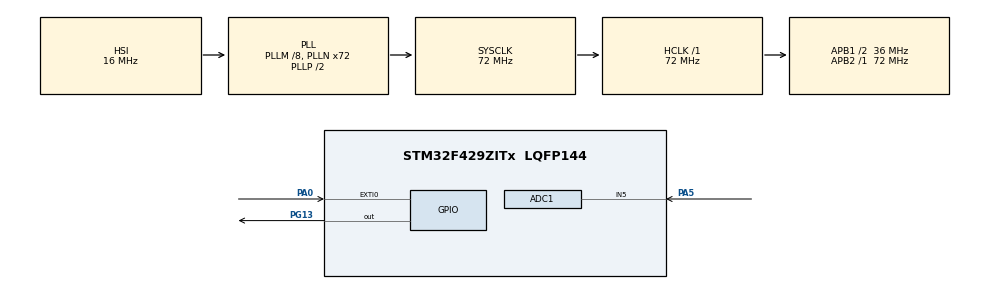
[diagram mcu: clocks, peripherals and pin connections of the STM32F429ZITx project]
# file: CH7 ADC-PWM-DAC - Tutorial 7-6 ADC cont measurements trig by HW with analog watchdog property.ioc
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ADC1.Channel-1\#ChannelRegularConversion=ADC_CHANNEL_5
ADC1.ContinuousConvMode=ENABLE
ADC1.EnableAnalogWatchDog=true
ADC1.HighThreshold=3586
ADC1.ITMode=ENABLE
ADC1.LowThreshold=512
ADC1.NbrOfConversionFlag=1
ADC1.Rank-1\#ChannelRegularConversion=1
ADC1.SamplingTime-1\#ChannelRegularConversion=ADC_SAMPLETIME_480CYCLES
ADC1.WatchdogChannel=ADC_CHANNEL_5
ADC1.master=1
Mcu.Family=STM32F4
Mcu.Name=STM32F429ZITx
Mcu.Package=LQFP144
NVIC.ADC_IRQn=true\:1\:0\:true\:false\:true\:true\:true\:true
NVIC.EXTI0_IRQn=true\:1\:0\:true\:false\:true\:true\:true\:true
NVIC.PriorityGroup=NVIC_PRIORITYGROUP_1
PA0/WKUP.Signal=GPXTI0
PA5.Signal=ADCx_IN5
PG13.Signal=GPIO_Output
ProjectManager.HeapSize=0x200
ProjectManager.StackSize=0x400
ProjectManager.TargetToolchain=STM32CubeIDE
RCC.48MHZClocksFreq_Value=20571428.57142857
RCC.AHBFreq_Value=72000000
RCC.APB1CLKDivider=RCC_HCLK_DIV2
RCC.APB1Freq_Value=36000000
RCC.APB1TimFreq_Value=72000000
RCC.APB2Freq_Value=72000000
RCC.APB2TimFreq_Value=72000000
RCC.CortexFreq_Value=72000000
RCC.HCLKFreq_Value=72000000
RCC.HSE_VALUE=8000000
RCC.HSI_VALUE=16000000
RCC.LSE_VALUE=32768
RCC.PLLM=8
RCC.PLLN=72
RCC.PLLQ=7
RCC.SYSCLKFreq_VALUE=72000000
RCC.SYSCLKSource=RCC_SYSCLKSOURCE_PLLCLK
RCC.VCOOutputFreq_Value=144000000
SH.ADCx_IN5.0=ADC2_IN5
SH.ADCx_IN5.1=ADC1_IN5,IN5
board=STM32F429I-DISC1

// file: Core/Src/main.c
/* USER CODE BEGIN Header */
/**
  ******************************************************************************
  * @file           : main.c
  * @brief          : Main program body
  ******************************************************************************
  * @attention
  *
  * Copyright (c) 2024 STMicroelectronics.
  * All rights reserved.
  *
  * This software is licensed under terms that can be found in the LICENSE file
  * in the root directory of this software component.
  * If no LICENSE file comes with this software, it is provided AS-IS.
  *
  ******************************************************************************
  */

	/***************************** Tutorial Tags ******************************
	 ADC continuous measurements
	 Hardware trigger EXTI line
	 **************************************************************************/

	/* 7.4.1 ADC Usage C Language: ******************************************
	* Tutorial 7-6: Usage of the ADC module with analog watchdog property, the C code
	*

    In this tutorial, form a project with the following specificvation:

    ADC2 Channel 5 is configured to be triggered by the onboard user button to take
    measurements of a potentiometer in continous mode in the infinite loop.
    The watchdog property of the ADC is set with low and high threshold levels
    as 512 and 3586, respectively. We should also enable the end of conversion and
    watchdog interrupts.

    After the project is compiled and run, ADC is triggered when the onboard
	button is pressed. Once 100 conversions are done, obtained values are summed and
	averaged in an infinite loop. If the analog value is above or below the threshold
	levels, then the watchdog interrupt is triggered during the conversion operation.
	Then, the variable adcWatchdogFlag is set and the onboard green LED connected
	to pin PG13 is turned on in the watchdog callback function. The adcWatchdogFlag
	is checked in the infinite loop in the main function. If this variable has been set in
	the callback function, then the ADC is stopped and onboard green LED is turned
	off after 2 s.
	***************************************************************************/

/* USER CODE END Header */
#include "main.h"

/* USER CODE BEGIN PD */
#define CONV_NUM 100
/* USER CODE END PD */

ADC_HandleTypeDef hadc1;

/* USER CODE BEGIN PV */
//uint8_t adcWatchdogFlag;
//uint8_t adcState;

uint32_t adcValue [CONV_NUM];
uint32_t adcSum, adcAve;
int32_t   counter;
uint8_t adcWatchdogFlag, flag_count;

/* USER CODE END PV */

void SystemClock_Config(void);
static void MX_GPIO_Init(void);
static void MX_ADC1_Init(void);

int main(void)
{

  /* MCU Configuration--------------------------------------------------------*/

  /* Reset of all peripherals, Initializes the Flash interface and the Systick. */
  HAL_Init();

  /* Configure the system clock */
  SystemClock_Config();

  /* Initialize all configured peripherals */
  MX_GPIO_Init();
  MX_ADC1_Init();

  /* Infinite loop */
  /* USER CODE BEGIN WHILE */
  while (1)
  {
   if(adcWatchdogFlag){

	   adcWatchdogFlag = 0;
	   HAL_Delay(2000);
	   HAL_GPIO_WritePin(GPIOG, GPIO_PIN_13, GPIO_PIN_RESET);

	   // Stop ADC if watchdog flag has set more than 5 times
	   flag_count++;
	   if (flag_count > 5){
		   HAL_ADC_Stop_IT(&hadc1);
	   }
	   else{
		   HAL_ADC_Start_IT(&hadc1);
	   }

	   HAL_Delay(100);
   }
   else if (counter == CONV_NUM){
	   for (int i=0; i<CONV_NUM; ++i){
		   adcSum += adcValue[i];
	   }
	   adcAve  = adcSum/CONV_NUM;
	   adcSum =  0; counter = 0;
	   HAL_ADC_Start_IT(&hadc1);
   }
  }
  /* USER CODE END 3 */
}

void SystemClock_Config(void)
{
  RCC_OscInitTypeDef RCC_OscInitStruct = {0};
  RCC_ClkInitTypeDef RCC_ClkInitStruct = {0};

  /** Configure the main internal regulator output voltage
  */
  __HAL_RCC_PWR_CLK_ENABLE();
  __HAL_PWR_VOLTAGESCALING_CONFIG(PWR_REGULATOR_VOLTAGE_SCALE3);

  /** Initializes the RCC Oscillators according to the specified parameters
  * in the RCC_OscInitTypeDef structure.
  */
  RCC_OscInitStruct.OscillatorType = RCC_OSCILLATORTYPE_HSI;
  RCC_OscInitStruct.HSIState = RCC_HSI_ON;
  RCC_OscInitStruct.HSICalibrationValue = RCC_HSICALIBRATION_DEFAULT;
  RCC_OscInitStruct.PLL.PLLState = RCC_PLL_ON;
  RCC_OscInitStruct.PLL.PLLSource = RCC_PLLSOURCE_HSI;
  RCC_OscInitStruct.PLL.PLLM = 8;
  RCC_OscInitStruct.PLL.PLLN = 72;
  RCC_OscInitStruct.PLL.PLLP = RCC_PLLP_DIV2;
  RCC_OscInitStruct.PLL.PLLQ = 7;
  if (HAL_RCC_OscConfig(&RCC_OscInitStruct) != HAL_OK)
  {
    Error_Handler();
  }

  /** Initializes the CPU, AHB and APB buses clocks
  */
  RCC_ClkInitStruct.ClockType = RCC_CLOCKTYPE_HCLK|RCC_CLOCKTYPE_SYSCLK
                              |RCC_CLOCKTYPE_PCLK1|RCC_CLOCKTYPE_PCLK2;
  RCC_ClkInitStruct.SYSCLKSource = RCC_SYSCLKSOURCE_PLLCLK;
  RCC_ClkInitStruct.AHBCLKDivider = RCC_SYSCLK_DIV1;
  RCC_ClkInitStruct.APB1CLKDivider = RCC_HCLK_DIV2;
  RCC_ClkInitStruct.APB2CLKDivider = RCC_HCLK_DIV1;

  if (HAL_RCC_ClockConfig(&RCC_ClkInitStruct, FLASH_LATENCY_2) != HAL_OK)
  {
    Error_Handler();
  }
}

static void MX_ADC1_Init(void)
{

  ADC_AnalogWDGConfTypeDef AnalogWDGConfig = {0};
  ADC_ChannelConfTypeDef sConfig = {0};

  /** Configure the global features of the ADC (Clock, Resolution, Data Alignment and number of conversion)
  */
  hadc1.Instance = ADC1;
  hadc1.Init.ClockPrescaler = ADC_CLOCK_SYNC_PCLK_DIV2;
  hadc1.Init.Resolution = ADC_RESOLUTION_12B;
  hadc1.Init.ScanConvMode = DISABLE;
  hadc1.Init.ContinuousConvMode = ENABLE;
  hadc1.Init.DiscontinuousConvMode = DISABLE;
  hadc1.Init.ExternalTrigConvEdge = ADC_EXTERNALTRIGCONVEDGE_NONE;
  hadc1.Init.ExternalTrigConv = ADC_SOFTWARE_START;
  hadc1.Init.DataAlign = ADC_DATAALIGN_RIGHT;
  hadc1.Init.NbrOfConversion = 1;
  hadc1.Init.DMAContinuousRequests = DISABLE;
  hadc1.Init.EOCSelection = ADC_EOC_SINGLE_CONV;
  if (HAL_ADC_Init(&hadc1) != HAL_OK)
  {
    Error_Handler();
  }

  /** Configure the analog watchdog
  */
  AnalogWDGConfig.WatchdogMode = ADC_ANALOGWATCHDOG_SINGLE_REG;
  AnalogWDGConfig.HighThreshold = 3586;
  AnalogWDGConfig.LowThreshold = 512;
  AnalogWDGConfig.Channel = ADC_CHANNEL_5;
  AnalogWDGConfig.ITMode = ENABLE;
  if (HAL_ADC_AnalogWDGConfig(&hadc1, &AnalogWDGConfig) != HAL_OK)
  {
    Error_Handler();
  }

  /** Configure for the selected ADC regular channel its corresponding rank in the sequencer and its sample time.
  */
  sConfig.Channel = ADC_CHANNEL_5;
  sConfig.Rank = 1;
  sConfig.SamplingTime = ADC_SAMPLETIME_480CYCLES;
  if (HAL_ADC_ConfigChannel(&hadc1, &sConfig) != HAL_OK)
  {
    Error_Handler();
  }

}

static void MX_GPIO_Init(void)
{
  GPIO_InitTypeDef GPIO_InitStruct = {0};

  /* GPIO Ports Clock Enable */
  __HAL_RCC_GPIOA_CLK_ENABLE();
  __HAL_RCC_GPIOG_CLK_ENABLE();

  /*Configure GPIO pin Output Level */
  HAL_GPIO_WritePin(GPIOG, GPIO_PIN_13, GPIO_PIN_RESET);

  /*Configure GPIO pin : PA0 */
  GPIO_InitStruct.Pin = GPIO_PIN_0;
  GPIO_InitStruct.Mode = GPIO_MODE_IT_RISING;
  GPIO_InitStruct.Pull = GPIO_NOPULL;
  HAL_GPIO_Init(GPIOA, &GPIO_InitStruct);

  /*Configure GPIO pin : PA5 */
  GPIO_InitStruct.Pin = GPIO_PIN_5;
  GPIO_InitStruct.Mode = GPIO_MODE_ANALOG;
  GPIO_InitStruct.Pull = GPIO_NOPULL;
  HAL_GPIO_Init(GPIOA, &GPIO_InitStruct);

  /*Configure GPIO pin : PG13 */
  GPIO_InitStruct.Pin = GPIO_PIN_13;
  GPIO_InitStruct.Mode = GPIO_MODE_OUTPUT_PP;
  GPIO_InitStruct.Pull = GPIO_NOPULL;
  GPIO_InitStruct.Speed = GPIO_SPEED_FREQ_LOW;
  HAL_GPIO_Init(GPIOG, &GPIO_InitStruct);

  /* EXTI interrupt init*/
  HAL_NVIC_SetPriority(EXTI0_IRQn, 1, 0);
  HAL_NVIC_EnableIRQ(EXTI0_IRQn);

}

/* USER CODE BEGIN 4 */

void HAL_GPIO_EXTI_Callback(uint16_t GPIO_Pin)
{
  if(GPIO_Pin == GPIO_PIN_0){
	  HAL_ADC_Start_IT(&hadc1);
  }
}

void HAL_ADC_ConvCpltCallback(ADC_HandleTypeDef *hadc)
{
	adcValue [counter] = HAL_ADC_GetValue(&hadc1);
	counter++;
	if(counter == CONV_NUM)
		HAL_ADC_Stop_IT(&hadc1);
}

void HAL_ADC_LevelOutOfWindowCallback(ADC_HandleTypeDef *hadc){
	adcWatchdogFlag = 1;
	HAL_GPIO_WritePin(GPIOG, GPIO_PIN_13, GPIO_PIN_SET);

}
/* USER CODE END 4 */

void Error_Handler(void)
{
  __disable_irq();
  while (1)
  {
  }
}
